AUTOSAR XML (schema 00046)
package /Composition_Lab
  sender receiver interface SRI_LightControl
    data LightControl: type=uint32
  sender receiver interface SRI_LightActuate
    data LightActuate: type=uint32
  sensor actuator sw component type SWC1_LightControlStatus
    provide port PP_SR_LightControl: provided-interface=SRI_LightControl
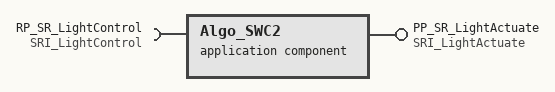
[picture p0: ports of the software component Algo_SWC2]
  application sw component type Algo_SWC2
    require port RP_SR_LightControl: required-interface=SRI_LightControl
    provide port PP_SR_LightActuate: provided-interface=SRI_LightActuate
  sensor actuator sw component type SWC3_LightActuate
    require port RP_SR_LightActuate: required-interface=SRI_LightActuate
  composition sw component type SW_Composite1
    provide port PP_SR_LightActuate_Comp: provided-interface=SRI_LightActuate
    component LC_SA_SWC1: type=SWC1_LightControlStatus
    component Algo_APP_SWC2: type=Algo_SWC2
    connect LC_SA_SWC1.PP_SR_LightControl -> Algo_APP_SWC2.RP_SR_LightControl
    delegate Algo_APP_SWC2.PP_SR_LightActuate <-> outer port PP_SR_LightActuate_Comp
  composition sw component type SW_Composite2
    component composite1: type=SW_Composite1
    component LA_SA_SWC3: type=SWC3_LightActuate
    connect composite1.PP_SR_LightActuate_Comp -> LA_SA_SWC3.RP_SR_LightActuate
